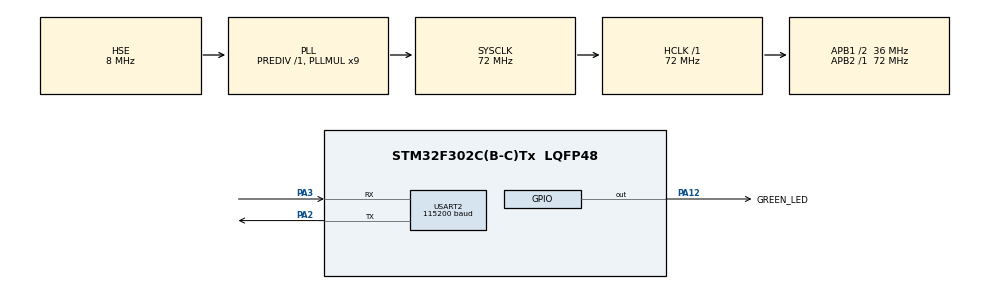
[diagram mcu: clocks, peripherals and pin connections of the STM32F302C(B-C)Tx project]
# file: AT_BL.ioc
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Mcu.Family=STM32F3
Mcu.Name=STM32F302C(B-C)Tx
Mcu.Package=LQFP48
NVIC.PriorityGroup=NVIC_PRIORITYGROUP_4
PA12.GPIO_Label=GREEN_LED
PA12.Signal=GPIO_Output
PA13.Mode=Serial_Wire
PA13.Signal=SYS_JTMS-SWDIO
PA14.Mode=Serial_Wire
PA14.Signal=SYS_JTCK-SWCLK
PA2.Mode=Asynchronous
PA2.Signal=USART2_TX
PA3.Mode=Asynchronous
PA3.Signal=USART2_RX
PF0-OSC_IN.Mode=HSE-External-Oscillator
PF0-OSC_IN.Signal=RCC_OSC_IN
PF1-OSC_OUT.Mode=HSE-External-Oscillator
PF1-OSC_OUT.Signal=RCC_OSC_OUT
ProjectManager.HeapSize=0x200
ProjectManager.StackSize=0x400
ProjectManager.TargetToolchain=STM32CubeIDE
RCC.AHBFreq_Value=72000000
RCC.APB1CLKDivider=RCC_HCLK_DIV2
RCC.APB1Freq_Value=36000000
RCC.APB1TimFreq_Value=72000000
RCC.APB2Freq_Value=72000000
RCC.APB2TimFreq_Value=72000000
RCC.CortexFreq_Value=72000000
RCC.HCLKFreq_Value=72000000
RCC.HSE_VALUE=8000000
RCC.HSI_VALUE=8000000
RCC.LSE_VALUE=32768
RCC.PLLMUL=RCC_PLL_MUL9
RCC.PLLSourceVirtual=RCC_PLLSOURCE_HSE
RCC.SYSCLKFreq_VALUE=72000000
RCC.SYSCLKSourceVirtual=RCC_SYSCLKSOURCE_PLLCLK
RCC.USBFreq_Value=72000000
USART2.BaudRate=115200
USART2.VirtualMode-Asynchronous=VM_ASYNC
board=custom

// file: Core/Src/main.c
/* USER CODE BEGIN Header */
/**
  ******************************************************************************
  * @file           : main.c
  * @brief          : Main program body
  ******************************************************************************
  * @attention
  *
  * Copyright (c) 2026 STMicroelectronics.
  * All rights reserved.
  *
  * This software is licensed under terms that can be found in the LICENSE file
  * in the root directory of this software component.
  * If no LICENSE file comes with this software, it is provided AS-IS.
  *
  ******************************************************************************
  */
/* USER CODE END Header */
#include "main.h"
#include "usart.h"
#include "gpio.h"

/* USER CODE BEGIN Includes */
#include "common.h"
#include "menu.h"
#include "upgrade.h"

/* USER CODE END Includes */

/* USER CODE BEGIN PD */
#define GREEN_LED_REG			GREEN_LED_GPIO_Port->ODR
extern pFunction JumpToApplication;
extern uint32_t JumpAddress;

/* USER CODE END PD */

void SystemClock_Config(void);

/* USER CODE BEGIN 0 */
#define GREEN_LED_BIT			GPIO_ODR_12

#define TOGGLE_BIT(REG, BIT)	((REG) ^= (BIT))

#define GREEN_LED(set)			((set) == SET ? SET_BIT(GREEN_LED_REG, GREEN_LED_BIT) : CLEAR_BIT(GREEN_LED_REG, GREEN_LED_BIT))

/* USER CODE END 0 */

int main(void)
{

  /* MCU Configuration--------------------------------------------------------*/

  /* Reset of all peripherals, Initializes the Flash interface and the Systick. */
  HAL_Init();

  /* Configure the system clock */
  SystemClock_Config();

  /* Initialize all configured peripherals */
  MX_GPIO_Init();
  MX_USART2_UART_Init();
  /* USER CODE BEGIN 2 */
  HAL_UART_Transmit(&huart2, (uint8_t *)"Inside Bootloader!!\r\n", 21, 100);

//  Set_Magic_Number();
  if (Magic_Number())
  {
Upgrade_program:

    /* Initialise Flash */
    FLASH_If_Init();

    /* Display main menu */
    Main_Menu ();
  }
  /* Keep the user application running */
  else
  {
     JumpToApp();// if not jumped, then go to while and wait pressing '9'
  }

  /* USER CODE END 2 */

  /* Infinite loop */
  /* USER CODE BEGIN WHILE */
  Serial_PutString((uint8_t *)"\r\n No user Program, Enter 9 to upgrade\r\n");
  uint32_t time_out_green_led = HAL_GetTick();
  uint8_t key = 0;
  uint32_t time_out_u = HAL_GetTick();
  while (1)
  {
	  if (HAL_GetTick() - time_out_green_led > 200)
	  {
		   TOGGLE_BIT(GREEN_LED_REG, GREEN_LED_BIT);
		   time_out_green_led = HAL_GetTick();
      }
	  if (SerialKeyPressed(&key) && key == 0x39)
	  {
		  goto Upgrade_program;
	  }
	  else if (HAL_GetTick()- time_out_u > 1000 )
  	  {
  	    Serial_PutByte('U'); // Upgrade mode
  	    time_out_u = HAL_GetTick();
  	    /* Clean the input path */
  	    __HAL_UART_FLUSH_DRREGISTER(&huart2);
  	  }
    /* USER CODE END WHILE */

  }
}

void SystemClock_Config(void)
{
  RCC_OscInitTypeDef RCC_OscInitStruct = {0};
  RCC_ClkInitTypeDef RCC_ClkInitStruct = {0};
  RCC_PeriphCLKInitTypeDef PeriphClkInit = {0};

  /** Initializes the RCC Oscillators according to the specified parameters
  * in the RCC_OscInitTypeDef structure.
  */
  RCC_OscInitStruct.OscillatorType = RCC_OSCILLATORTYPE_HSE;
  RCC_OscInitStruct.HSEState = RCC_HSE_ON;
  RCC_OscInitStruct.HSEPredivValue = RCC_HSE_PREDIV_DIV1;
  RCC_OscInitStruct.HSIState = RCC_HSI_ON;
  RCC_OscInitStruct.PLL.PLLState = RCC_PLL_ON;
  RCC_OscInitStruct.PLL.PLLSource = RCC_PLLSOURCE_HSE;
  RCC_OscInitStruct.PLL.PLLMUL = RCC_PLL_MUL9;
  if (HAL_RCC_OscConfig(&RCC_OscInitStruct) != HAL_OK)
  {
    Error_Handler();
  }

  /** Initializes the CPU, AHB and APB buses clocks
  */
  RCC_ClkInitStruct.ClockType = RCC_CLOCKTYPE_HCLK|RCC_CLOCKTYPE_SYSCLK
                              |RCC_CLOCKTYPE_PCLK1|RCC_CLOCKTYPE_PCLK2;
  RCC_ClkInitStruct.SYSCLKSource = RCC_SYSCLKSOURCE_PLLCLK;
  RCC_ClkInitStruct.AHBCLKDivider = RCC_SYSCLK_DIV1;
  RCC_ClkInitStruct.APB1CLKDivider = RCC_HCLK_DIV2;
  RCC_ClkInitStruct.APB2CLKDivider = RCC_HCLK_DIV1;

  if (HAL_RCC_ClockConfig(&RCC_ClkInitStruct, FLASH_LATENCY_2) != HAL_OK)
  {
    Error_Handler();
  }
  PeriphClkInit.PeriphClockSelection = RCC_PERIPHCLK_USART2;
  PeriphClkInit.Usart2ClockSelection = RCC_USART2CLKSOURCE_PCLK1;
  if (HAL_RCCEx_PeriphCLKConfig(&PeriphClkInit) != HAL_OK)
  {
    Error_Handler();
  }
}

void Error_Handler(void)
{
  __disable_irq();
  while (1)
  {
  }
}
